# MK26F18 register map
Vendor: Freescale Semiconductor, Inc.; Series: Kinetis_K; File version: 1.6
CPU: CM4 r0p1, little endian, no MPU, FPU, VTOR, 4 interrupt priority bits
Registers are 32-bit, read-write, reset 0x0 unless marked. A register's access mark holds for its fields unless they carry their own. Offsets are from the block's base; [hi:lo] are bit positions; {n}, {i} and the like mark numbered series; 'fields as' and 'values as' point back to an identical list.

## AXBS — Crossbar switch
Base 0x40004000; register names take the prefix AXBS_
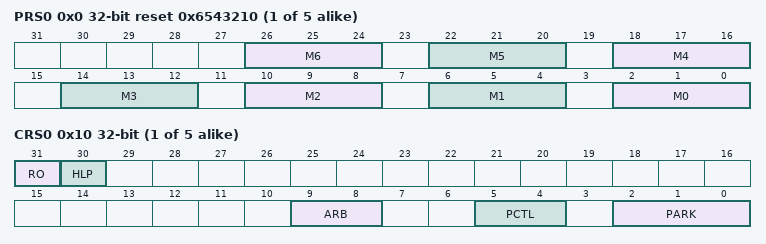
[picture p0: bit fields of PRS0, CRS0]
{0x0+0x100*i} PRS{i} (i=0..4) reset 0x6543210 — Priority Registers Slave
  [all] fields
    0=This master has level 1, or highest, priority when accessing the slave port; {v}=This master has level {v+1} priority when accessing the slave port (v=1..6); 7=This master has level 8, or lowest, priority when accessing the slave port
  [4n+2:4n] M{n} (n=0..6) — Master {n} Priority. Sets the arbitration priority for this port on the associated slave port.
{0x10+0x100*i} CRS{i} (i=0..4) — Control Register
  [31] RO — Read Only
    0=The slave port's registers are writeable; 1=The slave port's registers are read-only and cannot be written. Attempted writes have no effect on the registers and result in a bus error response.
  [30] HLP — Halt Low Priority
    0=The low power mode request has the highest priority for arbitration on this slave port; 1=The low power mode request has the lowest initial priority for arbitration on this slave port
  [9:8] ARB — Arbitration Mode
    0=Fixed priority; 1=Round-robin, or rotating, priority
  [5:4] PCTL — Parking Control
    0=When no master makes a request, the arbiter parks the slave port on the master port defined by the PARK field; 1=When no master makes a request, the arbiter parks the slave port on the last master to be in control of the slave port; 2=When no master makes a request, the slave port is not parked on a master and the arbiter drives all outputs to a constant safe state
  [2:0] PARK
    {v}=Park on master port M{v} (v=0..7)
{0x800+0x100*i} MGPCR{i} (i=0..2) — Master General Purpose Control Register
  [2:0] AULB — Arbitrates On Undefined Length Bursts
    0=No arbitration is allowed during an undefined length burst; 1=Arbitration is allowed at any time during an undefined length burst; 2=Arbitration is allowed after four beats of an undefined length burst; 3=Arbitration is allowed after eight beats of an undefined length burst; 4=Arbitration is allowed after 16 beats of an undefined length burst
{0x800+0x100*i} MGPCR{i} (i=4..6) — Master General Purpose Control Register
  fields as MGPCR0

## SDRAM — Synchronous DRAM Controller
Base 0x4000F000; register names take the prefix SDRAM_
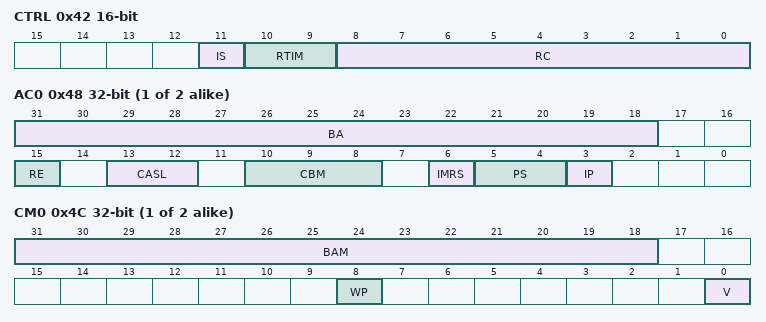
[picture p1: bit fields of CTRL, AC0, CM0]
0x42 CTRL 16-bit reset not defined — Control Register
  [11] IS — Initiate self-refresh command.
    0=Take no action or issue a selfx command to exit self refresh; 1=SDRAM controller sends a self command to both SDRAM blocks to put them in low-power, self-refresh state where they remain until IS is cleared. When IS is cleared, the controller sends a selfx command for the SDRAMs to exit self-refresh. The refresh counter is suspended while the SDRAMs are in self-refresh; the SDRAM controls the refresh period.
  [10:9] RTIM — Refresh timing
    0=3 clocks; 1=6 clocks; 2=9 clocks; 3=9 clocks
  [8:0] RC — Refresh count
{0x48+8i} AC{i} (i=0..1) (reset mask 0x8040) — Address and Control Register
  [31:18] BA — Base address register.
  [15] RE — Refresh enable
    0=Do not refresh associated DRAM block; 1=Refresh associated DRAM block
  [13:12] CASL — CAS Latency
  [10:8] CBM — Command bit location
  [6] IMRS — Initiate mode register set (mrs) command.
    0=Take no action; 1=Initiate mrs command
  [5:4] PS — Port size.
    0=32-bit port; 1=8-bit port; 2=16-bit port; 3=16-bit port
  [3] IP — Initiate precharge all (pall) command.
    0=Take no action; 1=A pall command is sent to the associated SDRAM block. During initialization, this command is executed after all DRAM controller registers are programmed. After IP is set, the next write to an appropriate SDRAM address generates the pall command to the SDRAM block.
{0x4C+8i} CM{i} (i=0..1) (reset mask 0x1) — Control Mask
  [31:18] BAM — Base address mask.
    0=The associated address bit is used in decoding the DRAM hit to a memory block; 1=The associated address bit is not used in the DRAM hit decode
  [8] WP — Write protect.
    0=Allow write accesses; 1=Ignore write accesses. The DRAM controller ignores write accesses to the memory block and an address exception occurs. Write accesses to a write-protected DRAM region are compared in the chip select module for a hit. If no hit occurs, an external bus cycle is generated. If this external bus cycle is not acknowledged, an access exception occurs.
  [0] V — Valid.
    0=Do not decode DRAM accesses; 1=Registers controlling the DRAM block are initialized; DRAM accesses can be decoded

## Notices in the file
Redistribution and use in source and binary forms, with or without modification,
are permitted provided that the following conditions are met:
o Redistributions of source code must retain the above copyright notice, this list
of conditions and the following disclaimer.
o Redistributions in binary form must reproduce the above copyright notice, this
list of conditions and the following disclaimer in the documentation and/or
other materials provided with the distribution.
o Neither the name of Freescale Semiconductor, Inc. nor the names of its
contributors may be used to endorse or promote products derived from this
software without specific prior written permission.
THIS SOFTWARE IS PROVIDED BY THE COPYRIGHT HOLDERS AND CONTRIBUTORS "AS IS" AND
ANY EXPRESS OR IMPLIED WARRANTIES, INCLUDING, BUT NOT LIMITED TO, THE IMPLIED
WARRANTIES OF MERCHANTABILITY AND FITNESS FOR A PARTICULAR PURPOSE ARE
DISCLAIMED. IN NO EVENT SHALL THE COPYRIGHT HOLDER OR CONTRIBUTORS BE LIABLE FOR
ANY DIRECT, INDIRECT, INCIDENTAL, SPECIAL, EXEMPLARY, OR CONSEQUENTIAL DAMAGES
(INCLUDING, BUT NOT LIMITED TO, PROCUREMENT OF SUBSTITUTE GOODS OR SERVICES;
LOSS OF USE, DATA, OR PROFITS; OR BUSINESS INTERRUPTION) HOWEVER CAUSED AND ON
ANY THEORY OF LIABILITY, WHETHER IN CONTRACT, STRICT LIABILITY, OR TORT
(INCLUDING NEGLIGENCE OR OTHERWISE) ARISING IN ANY WAY OUT OF THE USE OF THIS
SOFTWARE, EVEN IF ADVISED OF THE POSSIBILITY OF SUCH DAMAGE.
